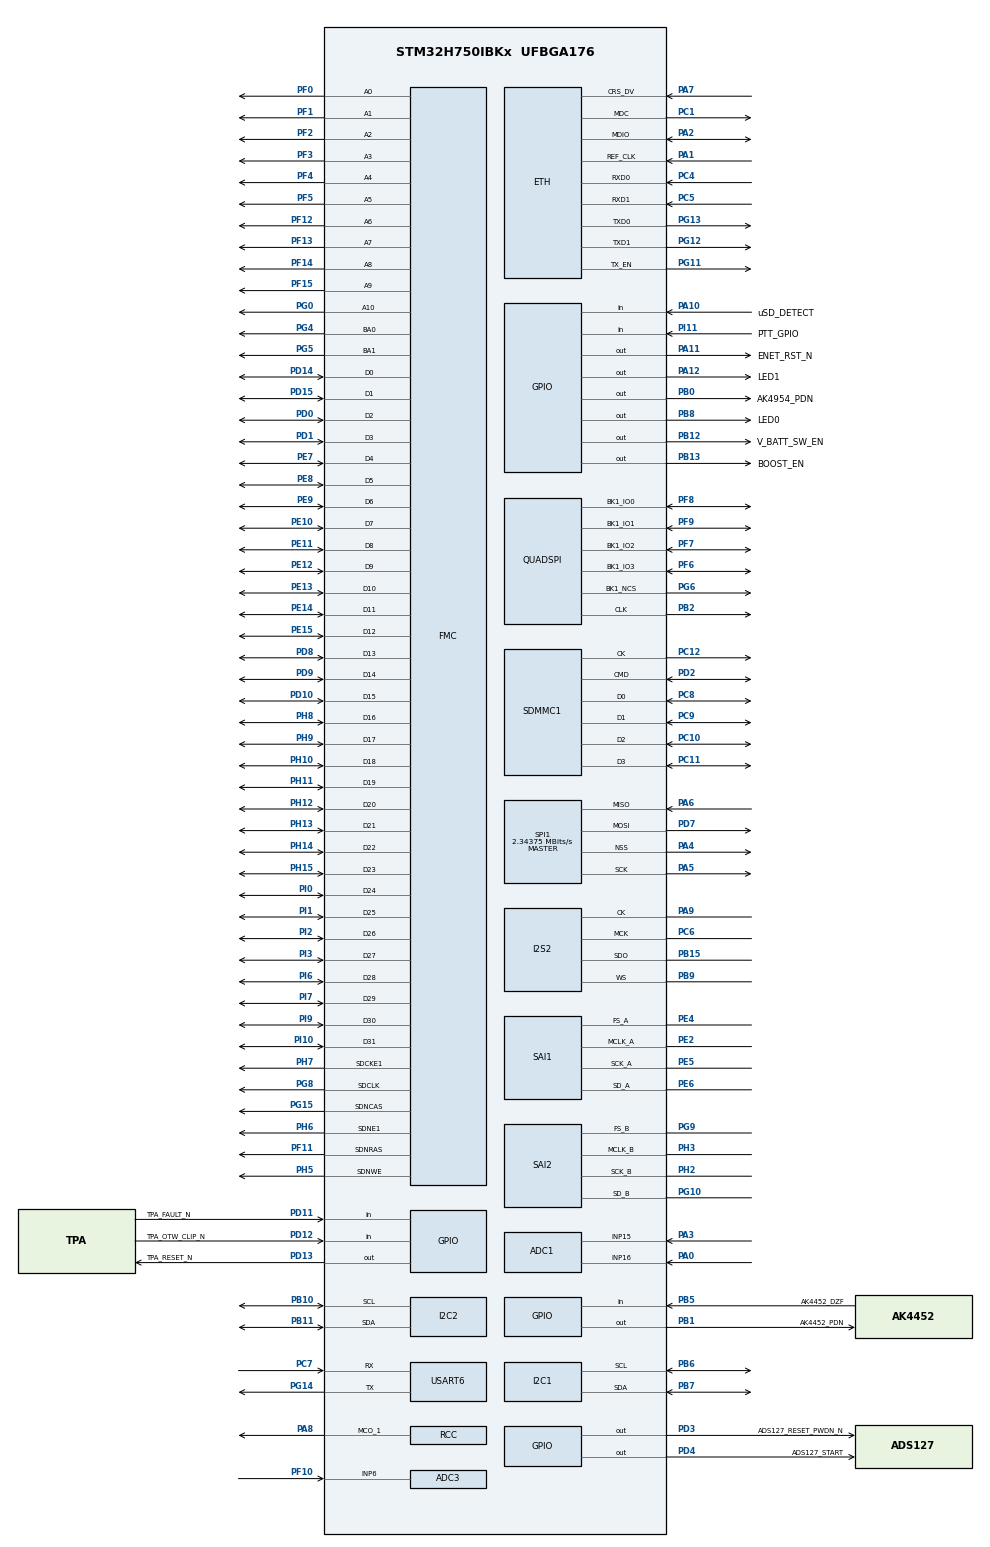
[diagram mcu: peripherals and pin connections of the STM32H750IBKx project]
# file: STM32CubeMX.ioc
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ADC1.Channel-0\#ChannelRegularConversion=ADC_CHANNEL_16
ADC1.ClockPrescaler=ADC_CLOCK_ASYNC_DIV16
ADC1.NbrOfConversionFlag=1
ADC1.OffsetNumber-0\#ChannelRegularConversion=ADC_OFFSET_NONE
ADC1.Rank-0\#ChannelRegularConversion=1
ADC1.SamplingTime-0\#ChannelRegularConversion=ADC_SAMPLETIME_1CYCLE_5
ADC1.master=1
ADC2.Channel-0\#ChannelRegularConversion=ADC_CHANNEL_15
ADC2.ClockPrescaler=ADC_CLOCK_ASYNC_DIV16
ADC2.NbrOfConversionFlag=1
ADC2.OffsetNumber-0\#ChannelRegularConversion=ADC_OFFSET_NONE
ADC2.Rank-0\#ChannelRegularConversion=1
ADC2.SamplingTime-0\#ChannelRegularConversion=ADC_SAMPLETIME_1CYCLE_5
ADC3.Channel-0\#ChannelRegularConversion=ADC_CHANNEL_6
ADC3.Channel-1\#ChannelRegularConversion=ADC_CHANNEL_6
ADC3.ClockPrescaler=ADC_CLOCK_ASYNC_DIV16
ADC3.NbrOfConversion=2
ADC3.NbrOfConversionFlag=1
ADC3.OffsetNumber-0\#ChannelRegularConversion=ADC_OFFSET_NONE
ADC3.OffsetNumber-1\#ChannelRegularConversion=ADC_OFFSET_NONE
ADC3.Rank-0\#ChannelRegularConversion=1
ADC3.Rank-1\#ChannelRegularConversion=2
ADC3.SamplingTime-0\#ChannelRegularConversion=ADC_SAMPLETIME_1CYCLE_5
ADC3.SamplingTime-1\#ChannelRegularConversion=ADC_SAMPLETIME_1CYCLE_5
Bdma.ADC3.0.Direction=DMA_PERIPH_TO_MEMORY
Bdma.ADC3.0.EventEnable=DISABLE
Bdma.ADC3.0.Instance=BDMA_Channel0
Bdma.ADC3.0.MemDataAlignment=DMA_MDATAALIGN_HALFWORD
Bdma.ADC3.0.MemInc=DMA_MINC_ENABLE
Bdma.ADC3.0.Mode=DMA_NORMAL
Bdma.ADC3.0.PeriphDataAlignment=DMA_PDATAALIGN_HALFWORD
Bdma.ADC3.0.PeriphInc=DMA_PINC_DISABLE
Bdma.ADC3.0.Polarity=HAL_DMAMUX_REQ_GEN_RISING
Bdma.ADC3.0.Priority=DMA_PRIORITY_LOW
Bdma.ADC3.0.RequestNumber=1
Bdma.ADC3.0.SignalID=NONE
Bdma.ADC3.0.SyncEnable=DISABLE
Bdma.ADC3.0.SyncPolarity=HAL_DMAMUX_SYNC_NO_EVENT
Bdma.ADC3.0.SyncRequestNumber=1
Bdma.ADC3.0.SyncSignalID=NONE
Bdma.Request0=ADC3
Bdma.RequestsNb=1
CORTEX_M7.CPU_DCache=Enabled
CORTEX_M7.CPU_ICache=Enabled
CORTEX_M7.MPU_Control=__NULL
Dma.Request0=SAI2_B
Dma.Request1=SAI1_A
Dma.Request2=SPI2_TX
Dma.SAI1_A.1.Direction=DMA_PERIPH_TO_MEMORY
Dma.SAI1_A.1.EventEnable=DISABLE
Dma.SAI1_A.1.FIFOMode=DMA_FIFOMODE_DISABLE
Dma.SAI1_A.1.Instance=DMA1_Stream2
Dma.SAI1_A.1.MemDataAlignment=DMA_MDATAALIGN_WORD
Dma.SAI1_A.1.MemInc=DMA_MINC_ENABLE
Dma.SAI1_A.1.Mode=DMA_CIRCULAR
Dma.SAI1_A.1.PeriphDataAlignment=DMA_PDATAALIGN_WORD
Dma.SAI1_A.1.PeriphInc=DMA_PINC_DISABLE
Dma.SAI1_A.1.Polarity=HAL_DMAMUX_REQ_GEN_RISING
Dma.SAI1_A.1.Priority=DMA_PRIORITY_LOW
Dma.SAI1_A.1.RequestNumber=1
Dma.SAI1_A.1.SignalID=NONE
Dma.SAI1_A.1.SyncEnable=DISABLE
Dma.SAI1_A.1.SyncPolarity=HAL_DMAMUX_SYNC_NO_EVENT
Dma.SAI1_A.1.SyncRequestNumber=1
Dma.SAI1_A.1.SyncSignalID=NONE
Dma.SAI2_B.0.Direction=DMA_MEMORY_TO_PERIPH
Dma.SAI2_B.0.EventEnable=ENABLE
Dma.SAI2_B.0.FIFOMode=DMA_FIFOMODE_DISABLE
Dma.SAI2_B.0.Instance=DMA1_Stream1
Dma.SAI2_B.0.MemDataAlignment=DMA_MDATAALIGN_WORD
Dma.SAI2_B.0.MemInc=DMA_MINC_ENABLE
Dma.SAI2_B.0.Mode=DMA_CIRCULAR
Dma.SAI2_B.0.PeriphDataAlignment=DMA_PDATAALIGN_WORD
Dma.SAI2_B.0.PeriphInc=DMA_PINC_DISABLE
Dma.SAI2_B.0.Polarity=HAL_DMAMUX_REQ_GEN_RISING
Dma.SAI2_B.0.Priority=DMA_PRIORITY_LOW
Dma.SAI2_B.0.RequestNumber=1
Dma.SAI2_B.0.SignalID=NONE
Dma.SAI2_B.0.SyncEnable=DISABLE
Dma.SAI2_B.0.SyncPolarity=HAL_DMAMUX_SYNC_NO_EVENT
Dma.SAI2_B.0.SyncRequestNumber=1
Dma.SAI2_B.0.SyncSignalID=NONE
Dma.SPI2_TX.2.Direction=DMA_MEMORY_TO_PERIPH
Dma.SPI2_TX.2.EventEnable=DISABLE
Dma.SPI2_TX.2.FIFOMode=DMA_FIFOMODE_ENABLE
Dma.SPI2_TX.2.FIFOThreshold=DMA_FIFO_THRESHOLD_HALFFULL
Dma.SPI2_TX.2.Instance=DMA1_Stream0
Dma.SPI2_TX.2.MemBurst=DMA_MBURST_SINGLE
Dma.SPI2_TX.2.MemDataAlignment=DMA_MDATAALIGN_WORD
Dma.SPI2_TX.2.MemInc=DMA_MINC_ENABLE
Dma.SPI2_TX.2.Mode=DMA_CIRCULAR
Dma.SPI2_TX.2.PeriphBurst=DMA_PBURST_SINGLE
Dma.SPI2_TX.2.PeriphDataAlignment=DMA_PDATAALIGN_WORD
Dma.SPI2_TX.2.PeriphInc=DMA_PINC_DISABLE
Dma.SPI2_TX.2.Polarity=HAL_DMAMUX_REQ_GEN_RISING
Dma.SPI2_TX.2.Priority=DMA_PRIORITY_VERY_HIGH
Dma.SPI2_TX.2.RequestNumber=1
Dma.SPI2_TX.2.SignalID=NONE
Dma.SPI2_TX.2.SyncEnable=DISABLE
Dma.SPI2_TX.2.SyncPolarity=HAL_DMAMUX_SYNC_NO_EVENT
Dma.SPI2_TX.2.SyncRequestNumber=1
Dma.SPI2_TX.2.SyncSignalID=NONE
ETH.MediaInterface=HAL_ETH_RMII_MODE
FMC.CASLatency1=FMC_SDRAM_CAS_LATENCY_2
FMC.ColumnBitsNumber1=FMC_SDRAM_COLUMN_BITS_NUM_8
FMC.ReadBurst1=FMC_SDRAM_RBURST_ENABLE
FMC.ReadPipeDelay1=FMC_SDRAM_RPIPE_DELAY_0
FMC.SDClockPeriod1=FMC_SDRAM_CLOCK_DISABLE
I2S2.AudioFreq=I2S_AUDIOFREQ_8K
I2S2.DataFormat=I2S_DATAFORMAT_32B
I2S2.ErrorAudioFreq=0.32 %
I2S2.FullDuplexMode=I2S_MODE_SLAVE_FD
I2S2.Instance=SPI$Index
I2S2.Mode=I2S_MODE_MASTER_TX
I2S2.RealAudioFreq=8.026 KHz
I2S2.VirtualMode=I2S_MODE_MASTER
Mcu.Family=STM32H7
Mcu.Name=STM32H750IBKx
Mcu.Package=UFBGA176
NVIC.BDMA_Channel0_IRQn=true\:0\:0\:false\:false\:true\:false\:true
NVIC.DMA1_Stream0_IRQn=true\:0\:0\:false\:false\:true\:false\:true
NVIC.DMA1_Stream1_IRQn=true\:0\:0\:false\:false\:true\:false\:true
NVIC.DMA1_Stream2_IRQn=true\:0\:0\:false\:false\:true\:false\:true
NVIC.DMAMUX1_OVR_IRQn=true\:0\:0\:false\:false\:true\:false\:true
NVIC.I2C1_ER_IRQn=true\:0\:0\:false\:false\:true\:true\:true
NVIC.I2C1_EV_IRQn=true\:0\:0\:false\:false\:true\:true\:true
NVIC.PriorityGroup=NVIC_PRIORITYGROUP_4
NVIC.SAI2_IRQn=true\:0\:0\:false\:false\:true\:true\:true
NVIC.SPI2_IRQn=true\:0\:0\:false\:false\:true\:true\:true
NVIC.TIM6_DAC_IRQn=true\:0\:0\:false\:false\:true\:false\:true
NVIC.TimeBase=TIM6_DAC_IRQn
NVIC.TimeBaseIP=TIM6
NVIC.USART6_IRQn=true\:0\:0\:false\:false\:true\:true\:true
PA0.Mode=IN16-Single-Ended
PA0.Signal=ADC1_INP16
PA1.Mode=RMII
PA1.Signal=ETH_REF_CLK
PA10.GPIO_Label=uSD_DETECT
PA10.Signal=GPIO_Input
PA11.GPIO_Label=ENET_RST_N
PA11.PinState=GPIO_PIN_SET
PA11.Signal=GPIO_Output
PA12.GPIO_Label=LED1
PA12.Signal=GPIO_Output
PA2.Mode=RMII
PA2.Signal=ETH_MDIO
PA3.Signal=ADCx_INP15
PA4.GPIO_Speed=GPIO_SPEED_FREQ_VERY_HIGH
PA4.Mode=NSS_Signal_Hard_Output
PA4.Signal=SPI1_NSS
PA5.Mode=Full_Duplex_Master
PA5.Signal=SPI1_SCK
PA6.Mode=Full_Duplex_Master
PA6.Signal=SPI1_MISO
PA7.Mode=RMII
PA7.Signal=ETH_CRS_DV
PA8.Mode=Clock-out-1
PA8.Signal=RCC_MCO_1
PA9.GPIO_Speed=GPIO_SPEED_FREQ_HIGH
PA9.Mode=Half_Duplex_Master
PA9.Signal=I2S2_CK
PB0.GPIO_Label=AK4954_PDN
PB0.Signal=GPIO_Output
PB1.GPIO_Label=AK4452_PDN
PB1.Signal=GPIO_Output
PB10.Mode=I2C
PB10.Signal=I2C2_SCL
PB11.Mode=I2C
PB11.Signal=I2C2_SDA
PB12.GPIO_Label=V_BATT_SW_EN
PB12.Signal=GPIO_Output
PB13.GPIO_Label=BOOST_EN
PB13.Signal=GPIO_Output
PB14.GPIO_Speed=GPIO_SPEED_FREQ_HIGH
PB14.Signal=I2S2_SDI
PB15.GPIO_Speed=GPIO_SPEED_FREQ_HIGH
PB15.Mode=Half_Duplex_Master
PB15.Signal=I2S2_SDO
PB2.Mode=Single Bank 1
PB2.Signal=QUADSPI_CLK
PB5.GPIO_Label=AK4452_DZF
PB5.Signal=GPIO_Input
PB6.Mode=I2C
PB6.Signal=I2C1_SCL
PB7.Mode=I2C
PB7.Signal=I2C1_SDA
PB8.GPIO_Label=LED0
PB8.Signal=GPIO_Output
PB9.GPIO_FM9=__NULL
PB9.GPIO_Speed=GPIO_SPEED_FREQ_HIGH
PB9.Mode=Half_Duplex_Master
PB9.Signal=I2S2_WS
PC0.Signal=ADCx_INP10
PC1.Mode=RMII
PC1.Signal=ETH_MDC
PC10.Mode=SD_4_bits_Wide_bus
PC10.Signal=SDMMC1_D2
PC11.Mode=SD_4_bits_Wide_bus
PC11.Signal=SDMMC1_D3
PC12.Mode=SD_4_bits_Wide_bus
PC12.Signal=SDMMC1_CK
PC14-OSC32_IN\ (OSC32_IN).Mode=LSE-External-Oscillator
PC14-OSC32_IN\ (OSC32_IN).Signal=RCC_OSC32_IN
PC15-OSC32_OUT\ (OSC32_OUT).Mode=LSE-External-Oscillator
PC15-OSC32_OUT\ (OSC32_OUT).Signal=RCC_OSC32_OUT
PC4.Mode=RMII
PC4.Signal=ETH_RXD0
PC5.Mode=RMII
PC5.Signal=ETH_RXD1
PC6.GPIO_Speed=GPIO_SPEED_FREQ_HIGH
PC6.Mode=Master_Clock_Activated
PC6.Signal=I2S2_MCK
PC7.Mode=Asynchronous
PC7.Signal=USART6_RX
PC8.Mode=SD_4_bits_Wide_bus
PC8.Signal=SDMMC1_D0
PC9.Mode=SD_4_bits_Wide_bus
PC9.Signal=SDMMC1_D1
PD0.Signal=FMC_D2_DA2
PD1.Signal=FMC_D3_DA3
PD10.Signal=FMC_D15_DA15
PD11.GPIO_Label=TPA_FAULT_N
PD11.Signal=GPIO_Input
PD12.GPIO_Label=TPA_OTW_CLIP_N
PD12.Signal=GPIO_Input
PD13.GPIO_Label=TPA_RESET_N
PD13.Signal=GPIO_Output
PD14.Signal=FMC_D0_DA0
PD15.Signal=FMC_D1_DA1
PD2.Mode=SD_4_bits_Wide_bus
PD2.Signal=SDMMC1_CMD
PD3.GPIO_Label=ADS127_RESET_PWDN_N
PD3.Signal=GPIO_Output
PD4.GPIO_Label=ADS127_START
PD4.Signal=GPIO_Output
PD5.Signal=USART2_TX
PD6.Signal=USART2_RX
PD7.Mode=Full_Duplex_Master
PD7.Signal=SPI1_MOSI
PD8.Signal=FMC_D13_DA13
PD9.Signal=FMC_D14_DA14
PE0.Signal=FMC_NBL0
PE1.Signal=FMC_NBL1
PE10.Signal=FMC_D7_DA7
PE11.Signal=FMC_D8_DA8
PE12.Signal=FMC_D9_DA9
PE13.Signal=FMC_D10_DA10
PE14.Signal=FMC_D11_DA11
PE15.Signal=FMC_D12_DA12
PE2.Mode=SAI_A_MasterWithClock
PE2.Signal=SAI1_MCLK_A
PE4.Mode=SAI_A_MasterWithClock
PE4.Signal=SAI1_FS_A
PE5.Mode=SAI_A_MasterWithClock
PE5.Signal=SAI1_SCK_A
PE6.Mode=SAI_A_MasterWithClock
PE6.Signal=SAI1_SD_A
PE7.Signal=FMC_D4_DA4
PE8.Signal=FMC_D5_DA5
PE9.Signal=FMC_D6_DA6
PF0.Signal=FMC_A0
PF1.Signal=FMC_A1
PF10.Mode=IN6-Single-Ended
PF10.Signal=ADC3_INP6
PF11.Signal=FMC_SDNRAS
PF12.Signal=FMC_A6
PF13.Signal=FMC_A7
PF14.Signal=FMC_A8
PF15.Signal=FMC_A9
PF2.Signal=FMC_A2
PF3.Signal=FMC_A3
PF4.Signal=FMC_A4
PF5.Signal=FMC_A5
PF6.Mode=Single Bank 1
PF6.Signal=QUADSPI_BK1_IO3
PF7.Mode=Single Bank 1
PF7.Signal=QUADSPI_BK1_IO2
PF8.Mode=Single Bank 1
PF8.Signal=QUADSPI_BK1_IO0
PF9.Mode=Single Bank 1
PF9.Signal=QUADSPI_BK1_IO1
PG0.Signal=FMC_A10
PG1.Signal=FMC_A11
PG10.Mode=SAI_B_MasterWithClock
PG10.Signal=SAI2_SD_B
PG11.Mode=RMII
PG11.Signal=ETH_TX_EN
PG12.Mode=RMII
PG12.Signal=ETH_TXD1
PG13.Mode=RMII
PG13.Signal=ETH_TXD0
PG14.Mode=Asynchronous
PG14.Signal=USART6_TX
PG15.Signal=FMC_SDNCAS
PG4.Signal=FMC_A14_BA0
PG5.Signal=FMC_A15_BA1
PG6.Mode=Single Bank 1
PG6.Signal=QUADSPI_BK1_NCS
PG8.Signal=FMC_SDCLK
PG9.Mode=SAI_B_MasterWithClock
PG9.Signal=SAI2_FS_B
PH0-OSC_IN\ (PH0).Mode=HSE-External-Oscillator
PH0-OSC_IN\ (PH0).Signal=RCC_OSC_IN
PH1-OSC_OUT\ (PH1).Mode=HSE-External-Oscillator
PH1-OSC_OUT\ (PH1).Signal=RCC_OSC_OUT
PH10.Signal=FMC_D18
PH11.Signal=FMC_D19
PH12.Signal=FMC_D20
PH13.Signal=FMC_D21
PH14.Signal=FMC_D22
PH15.Signal=FMC_D23
PH2.Mode=SAI_B_MasterWithClock
PH2.Signal=SAI2_SCK_B
PH3.GPIO_Mode=GPIO_MODE_AF_PP
PH3.GPIO_PuPd=GPIO_NOPULL
PH3.GPIO_Speed=GPIO_SPEED_FREQ_LOW
PH3.Mode=SAI_B_MasterWithClock
PH3.Signal=SAI2_MCLK_B
PH4.Signal=ADC3_INP15
PH5.Signal=FMC_SDNWE
PH6.Mode=SdramChipSelect2_1
PH6.Signal=FMC_SDNE1
PH7.Mode=SdramChipSelect2_1
PH7.Signal=FMC_SDCKE1
PH8.Signal=FMC_D16
PH9.Signal=FMC_D17
PI0.Signal=FMC_D24
PI1.Signal=FMC_D25
PI10.Signal=FMC_D31
PI11.GPIO_Label=PTT_GPIO
PI11.Signal=GPIO_Input
PI2.Signal=FMC_D26
PI3.Signal=FMC_D27
PI4.Signal=FMC_NBL2
PI5.Signal=FMC_NBL3
PI6.Signal=FMC_D28
PI7.Signal=FMC_D29
PI9.Signal=FMC_D30
ProjectManager.HeapSize=0x1000
ProjectManager.StackSize=0x1900
ProjectManager.TargetToolchain=STM32CubeIDE
RCC.ADCFreq_Value=150000000
RCC.APB1Freq_Value=40000000
RCC.APB2Freq_Value=40000000
RCC.APB3Freq_Value=40000000
RCC.APB4Freq_Value=40000000
RCC.CortexFreq_Value=80000000
RCC.D1PPRE=RCC_APB3_DIV2
RCC.D2PPRE1=RCC_APB1_DIV2
RCC.D2PPRE2=RCC_APB2_DIV2
RCC.D3PPRE=RCC_APB4_DIV2
RCC.DIVM1=2
RCC.DIVM2=2
RCC.DIVN1=64
RCC.DIVN2=12
RCC.DIVP1=10
RCC.DIVP2=1
RCC.DIVQ1=4
RCC.DIVQ2=4
RCC.DIVR2=1
RCC.HCLKFreq_Value=80000000
RCC.I2C123CLockSelection=RCC_I2C123CLKSOURCE_HSI
RCC.PLL2FRACN=0
RCC.PLL3FRACN=0
RCC.PLLFRACN=0
RCC.PLLSourceVirtual=RCC_PLLSOURCE_HSE
RCC.PWR_Regulator_Voltage_Scale=PWR_REGULATOR_VOLTAGE_SCALE1
RCC.QSPICLockSelection=RCC_QSPICLKSOURCE_PLL2
RCC.SAI1CLockSelection=RCC_SAI1CLKSOURCE_PLL2
RCC.SAI23CLockSelection=RCC_SAI23CLKSOURCE_PLL2
RCC.SDMMC1CLockSelection=RCC_SDMMCCLKSOURCE_PLL2
RCC.SPI123CLockSelection=RCC_SPI123CLKSOURCE_PLL2
RCC.SYSCLKFreq_VALUE=80000000
RCC.SYSCLKSource=RCC_SYSCLKSOURCE_PLLCLK
RCC.USBFreq_Value=200000000
SAI1.ActiveFrameLength-SAI_A_MasterWithClock=32
SAI1.AudioFrequency-SAI_A_MasterWithClock=SAI_AUDIO_FREQUENCY_MCKDIV
SAI1.AudioMode-SAI_A_MasterWithClock=SAI_MODEMASTER_RX
SAI1.DataSize-SAI_A_MasterWithClock=SAI_DATASIZE_32
SAI1.ErrorAudioFreq-SAI_A_MasterWithClock=-46.66 %
SAI1.FSOffset-SAI_A_MasterWithClock=SAI_FS_BEFOREFIRSTBIT
SAI1.FSPolarity-SAI_A_MasterWithClock=SAI_FS_ACTIVE_HIGH
SAI1.FirstBitOffset-SAI_A_MasterWithClock=0
SAI1.FrameLength-SAI_A_MasterWithClock=64
SAI1.Instance-SAI_A_MasterWithClock=SAI$Index_Block_A
SAI1.MClockEnable-SAI_A_MasterWithClock=SAI_MASTERCLOCK_ENABLE
SAI1.Mckdiv-SAI_A_MasterWithClock=1
SAI1.RealAudioFreq-SAI_A_MasterWithClock=292.968 KHz
SAI1.SlotActive-SAI_A_MasterWithClock=0x0000FFFF
SAI1.SlotNumber-SAI_A_MasterWithClock=2
SAI1.SlotSize-SAI_A_MasterWithClock=SAI_SLOTSIZE_32B
SAI1.Synchro-SAI_A_MasterWithClock=SAI_ASYNCHRONOUS
SAI1.VirtualMode-SAI_A_MasterWithClock=VM_MASTER
SAI1.VirtualSlotActive-SAI_A_MasterWithClock=SAI_SLOTACTIVE_ALL
SAI1.VirtualSlotActive0-SAI_A_MasterWithClock=false
SAI2.AudioFrequency-SAI_B_MasterWithClock=SAI_AUDIO_FREQUENCY_MCKDIV
SAI2.BasicDataSize-SAI_B_MasterWithClock=SAI_PROTOCOL_DATASIZE_32BIT
SAI2.BasicSlotNumber-SAI_B_MasterWithClock=2
SAI2.ErrorAudioFreq-SAI_B_MasterWithClock=-46.66 %
SAI2.InitProtocol-SAI_B_MasterWithClock=Enable
SAI2.Instance-SAI_B_MasterWithClock=SAI$Index_Block_B
SAI2.MClockEnable-SAI_B_MasterWithClock=SAI_MASTERCLOCK_ENABLE
SAI2.Mckdiv-SAI_B_MasterWithClock=2
SAI2.OutputDrive-SAI_B_MasterWithClock=SAI_OUTPUTDRIVE_ENABLE
SAI2.RealAudioFreq-SAI_B_MasterWithClock=146.484 KHz
SAI2.VirtualMode-SAI_B_MasterWithClock=VM_MASTER
SAI2.VirtualProtocol-SAI_B_BASIC=VM_BASIC_PROTOCOL
SDMMC1.ClockDiv=100
SDMMC1.HardwareFlowControl=SDMMC_HARDWARE_FLOW_CONTROL_ENABLE
SH.ADCx_INP10.0=ADC1_INP10
SH.ADCx_INP10.1=ADC3_INP10
SH.ADCx_INP15.0=ADC1_INP15,IN15-Single-Ended
SH.ADCx_INP15.1=ADC2_INP15,IN15-Single-Ended
SH.FMC_A0.0=FMC_A0,11b-sda1
SH.FMC_A1.0=FMC_A1,11b-sda1
SH.FMC_A10.0=FMC_A10,11b-sda1
SH.FMC_A11.0=FMC_A11
SH.FMC_A14_BA0.0=FMC_A14
SH.FMC_A14_BA0.1=FMC_BA0,FourSdramBanks1
SH.FMC_A15_BA1.0=FMC_A15
SH.FMC_A15_BA1.1=FMC_BA1,FourSdramBanks1
SH.FMC_A2.0=FMC_A2,11b-sda1
SH.FMC_A3.0=FMC_A3,11b-sda1
SH.FMC_A4.0=FMC_A4,11b-sda1
SH.FMC_A5.0=FMC_A5,11b-sda1
SH.FMC_A6.0=FMC_A6,11b-sda1
SH.FMC_A7.0=FMC_A7,11b-sda1
SH.FMC_A8.0=FMC_A8,11b-sda1
SH.FMC_A9.0=FMC_A9,11b-sda1
SH.FMC_D0_DA0.0=FMC_D0,sd-32b-d1
SH.FMC_D10_DA10.0=FMC_D10,sd-32b-d1
SH.FMC_D11_DA11.0=FMC_D11,sd-32b-d1
SH.FMC_D12_DA12.0=FMC_D12,sd-32b-d1
SH.FMC_D13_DA13.0=FMC_D13,sd-32b-d1
SH.FMC_D14_DA14.0=FMC_D14,sd-32b-d1
SH.FMC_D15_DA15.0=FMC_D15,sd-32b-d1
SH.FMC_D16.0=FMC_D16,sd-32b-d1
SH.FMC_D17.0=FMC_D17,sd-32b-d1
SH.FMC_D18.0=FMC_D18,sd-32b-d1
SH.FMC_D19.0=FMC_D19,sd-32b-d1
SH.FMC_D1_DA1.0=FMC_D1,sd-32b-d1
SH.FMC_D20.0=FMC_D20,sd-32b-d1
SH.FMC_D21.0=FMC_D21,sd-32b-d1
SH.FMC_D22.0=FMC_D22,sd-32b-d1
SH.FMC_D23.0=FMC_D23,sd-32b-d1
SH.FMC_D24.0=FMC_D24,sd-32b-d1
SH.FMC_D25.0=FMC_D25,sd-32b-d1
SH.FMC_D26.0=FMC_D26,sd-32b-d1
SH.FMC_D27.0=FMC_D27,sd-32b-d1
SH.FMC_D28.0=FMC_D28,sd-32b-d1
SH.FMC_D29.0=FMC_D29,sd-32b-d1
SH.FMC_D2_DA2.0=FMC_D2,sd-32b-d1
SH.FMC_D30.0=FMC_D30,sd-32b-d1
SH.FMC_D31.0=FMC_D31,sd-32b-d1
SH.FMC_D3_DA3.0=FMC_D3,sd-32b-d1
SH.FMC_D4_DA4.0=FMC_D4,sd-32b-d1
SH.FMC_D5_DA5.0=FMC_D5,sd-32b-d1
SH.FMC_D6_DA6.0=FMC_D6,sd-32b-d1
SH.FMC_D7_DA7.0=FMC_D7,sd-32b-d1
SH.FMC_D8_DA8.0=FMC_D8,sd-32b-d1
SH.FMC_D9_DA9.0=FMC_D9,sd-32b-d1
SH.FMC_NBL0.0=FMC_NBL0
SH.FMC_NBL1.0=FMC_NBL1
SH.FMC_NBL2.0=FMC_NBL2
SH.FMC_NBL3.0=FMC_NBL3
SH.FMC_SDCLK.0=FMC_SDCLK,11b-sda1
SH.FMC_SDNCAS.0=FMC_SDNCAS,11b-sda1
SH.FMC_SDNRAS.0=FMC_SDNRAS,11b-sda1
SH.FMC_SDNWE.0=FMC_SDNWE,11b-sda1
SPI1.BaudRatePrescaler=SPI_BAUDRATEPRESCALER_64
SPI1.CalculateBaudRate=2.34375 MBits/s
SPI1.DataSize=SPI_DATASIZE_32BIT
SPI1.Direction=SPI_DIRECTION_2LINES
SPI1.Mode=SPI_MODE_MASTER
SPI1.VirtualNSS=VM_NSSHARD
SPI1.VirtualType=VM_MASTER
USART6.VirtualMode-Asynchronous=VM_ASYNC
VP_RCC_LSE.Mode=CRS SYNC Source LSE
VP_SAI2_VP_$IpInstance_SAIB_SAI_BASIC.Mode=SAI_B_BASIC
VP_SYS_VS_tim6.Mode=TIM6
board=custom

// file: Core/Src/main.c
/* USER CODE BEGIN Header */
/**
  ******************************************************************************
  * @file           : main.c
  * @brief          : Main program body
  ******************************************************************************
  * @attention
  *
  * <h2><center>&copy; Copyright (c) 2020 STMicroelectronics.
  * All rights reserved.</center></h2>
  *
  * This software component is licensed by ST under Ultimate Liberty license
  * SLA0044, the "License"; You may not use this file except in compliance with
  * the License. You may obtain a copy of the License at:
  *                             www.st.com/SLA0044
  *
  ******************************************************************************
  */
/* USER CODE END Header */

#include "main.h"
#include "string.h"

#if defined ( __ICCARM__ ) /*!< IAR Compiler */

#pragma location=0x30040000
ETH_DMADescTypeDef  DMARxDscrTab[ETH_RX_DESC_CNT]; /* Ethernet Rx DMA Descriptors */
#pragma location=0x30040060
ETH_DMADescTypeDef  DMATxDscrTab[ETH_TX_DESC_CNT]; /* Ethernet Tx DMA Descriptors */
#pragma location=0x30040200
uint8_t Rx_Buff[ETH_RX_DESC_CNT][ETH_MAX_PACKET_SIZE]; /* Ethernet Receive Buffers */

#elif defined ( __CC_ARM )  /* MDK ARM Compiler */

__attribute__((at(0x30040000))) ETH_DMADescTypeDef  DMARxDscrTab[ETH_RX_DESC_CNT]; /* Ethernet Rx DMA Descriptors */
__attribute__((at(0x30040060))) ETH_DMADescTypeDef  DMATxDscrTab[ETH_TX_DESC_CNT]; /* Ethernet Tx DMA Descriptors */
__attribute__((at(0x30040200))) uint8_t Rx_Buff[ETH_RX_DESC_CNT][ETH_MAX_PACKET_SIZE]; /* Ethernet Receive Buffer */

#elif defined ( __GNUC__ ) /* GNU Compiler */

ETH_DMADescTypeDef DMARxDscrTab[ETH_RX_DESC_CNT] __attribute__((section(".RxDecripSection"))); /* Ethernet Rx DMA Descriptors */
ETH_DMADescTypeDef DMATxDscrTab[ETH_TX_DESC_CNT] __attribute__((section(".TxDecripSection")));   /* Ethernet Tx DMA Descriptors */
uint8_t Rx_Buff[ETH_RX_DESC_CNT][ETH_MAX_PACKET_SIZE] __attribute__((section(".RxArraySection"))); /* Ethernet Receive Buffers */

#endif

ETH_TxPacketConfig TxConfig;
ADC_HandleTypeDef hadc1;
ADC_HandleTypeDef hadc2;
ADC_HandleTypeDef hadc3;
DMA_HandleTypeDef hdma_adc3;

ETH_HandleTypeDef heth;

I2C_HandleTypeDef hi2c1;
I2C_HandleTypeDef hi2c2;

I2S_HandleTypeDef hi2s2;
DMA_HandleTypeDef hdma_spi2_tx;

QSPI_HandleTypeDef hqspi;

SAI_HandleTypeDef hsai_BlockA1;
SAI_HandleTypeDef hsai_BlockB2;
DMA_HandleTypeDef hdma_sai1_a;
DMA_HandleTypeDef hdma_sai2_b;

SD_HandleTypeDef hsd1;

SPI_HandleTypeDef hspi1;

UART_HandleTypeDef huart6;

SDRAM_HandleTypeDef hsdram1;

void SystemClock_Config(void);
static void MX_GPIO_Init(void);
static void MX_BDMA_Init(void);
static void MX_DMA_Init(void);
static void MX_SPI1_Init(void);
static void MX_ADC2_Init(void);
static void MX_SAI1_Init(void);
static void MX_ADC3_Init(void);
static void MX_QUADSPI_Init(void);
static void MX_SAI2_Init(void);
static void MX_I2S2_Init(void);
static void MX_USART6_UART_Init(void);
static void MX_I2C1_Init(void);
static void MX_I2C2_Init(void);
static void MX_SDMMC1_SD_Init(void);
static void MX_ADC1_Init(void);
static void MX_FMC_Init(void);
static void MX_ETH_Init(void);

int main(void)
{

  /* Enable I-Cache---------------------------------------------------------*/
  SCB_EnableICache();

  /* Enable D-Cache---------------------------------------------------------*/
  SCB_EnableDCache();

  /* MCU Configuration--------------------------------------------------------*/

  /* Reset of all peripherals, Initializes the Flash interface and the Systick. */
  HAL_Init();

  /* Configure the system clock */
  SystemClock_Config();

  /* Initialize all configured peripherals */
  MX_GPIO_Init();
  MX_BDMA_Init();
  MX_DMA_Init();
  MX_SPI1_Init();
  MX_ADC2_Init();
  MX_SAI1_Init();
  MX_ADC3_Init();
  MX_QUADSPI_Init();
  MX_SAI2_Init();
  MX_I2S2_Init();
  MX_USART6_UART_Init();
  MX_I2C1_Init();
  MX_I2C2_Init();
  MX_SDMMC1_SD_Init();
  MX_ADC1_Init();
  MX_FMC_Init();
  MX_ETH_Init();
  /* USER CODE BEGIN 2 */
  srand(100);
 int a[20];
  for( int i = 0 ; i <= 20 ; i++ ) {
        a[i] = rand() % 50;
     }

int volatile * const p_reg = (int *) 0xD0000000;
volatile int badcnt = 0;

{
	int i;

	int Last = -1;
	for (i = 0; i < 1000000; i++)
	{
		p_reg[i] = i;
	}
	for (i = 0; i < 1000000; i++)
		{
			if(p_reg[i] != i)
			{
				//printf("Bad At %h", i);

				badcnt ++;
			}
			Last=p_reg[i];
		}

}

  /*
  FIL filTest;
  FATFS fs;
  disk_initialize(0);
  FRESULT res = f_mount(&fs, "", 0);
  res = f_open(&filTest, "LOG.TXT", FA_OPEN_ALWAYS | FA_WRITE);
  if(res == FR_OK)
	  {
	    UINT BytesWritten;
	    const char string[] = "Hello World\n";

	    f_lseek(&filTest, f_size(&filTest));
	     res = f_write(&filTest, string, strlen(string), &BytesWritten);
	    f_close(&filTest);
	  }
*/
  /* USER CODE END 2 */

  /* Infinite loop */
  while (1)
  {

  }
}

void SystemClock_Config(void)
{
  RCC_OscInitTypeDef RCC_OscInitStruct = {0};
  RCC_ClkInitTypeDef RCC_ClkInitStruct = {0};
  RCC_PeriphCLKInitTypeDef PeriphClkInitStruct = {0};
  RCC_CRSInitTypeDef RCC_CRSInitStruct = {0};

  /** Supply configuration update enable
  */
  HAL_PWREx_ConfigSupply(PWR_LDO_SUPPLY);
  /** Configure the main internal regulator output voltage
  */
  __HAL_PWR_VOLTAGESCALING_CONFIG(PWR_REGULATOR_VOLTAGE_SCALE1);

  while(!__HAL_PWR_GET_FLAG(PWR_FLAG_VOSRDY)) {}
  /** Configure LSE Drive Capability
  */
  HAL_PWR_EnableBkUpAccess();
  __HAL_RCC_LSEDRIVE_CONFIG(RCC_LSEDRIVE_LOW);
  /** Macro to configure the PLL clock source
  */
  __HAL_RCC_PLL_PLLSOURCE_CONFIG(RCC_PLLSOURCE_HSE);
  /** Initializes the CPU, AHB and APB busses clocks
  */
  RCC_OscInitStruct.OscillatorType = RCC_OSCILLATORTYPE_HSI|RCC_OSCILLATORTYPE_HSE
                              |RCC_OSCILLATORTYPE_LSE;
  RCC_OscInitStruct.HSEState = RCC_HSE_ON;
  RCC_OscInitStruct.LSEState = RCC_LSE_ON;
  RCC_OscInitStruct.HSIState = RCC_HSI_DIV1;
  RCC_OscInitStruct.HSICalibrationValue = RCC_HSICALIBRATION_DEFAULT;
  RCC_OscInitStruct.PLL.PLLState = RCC_PLL_ON;
  RCC_OscInitStruct.PLL.PLLSource = RCC_PLLSOURCE_HSE;
  RCC_OscInitStruct.PLL.PLLM = 2;
  RCC_OscInitStruct.PLL.PLLN = 64;
  RCC_OscInitStruct.PLL.PLLP = 10;
  RCC_OscInitStruct.PLL.PLLQ = 4;
  RCC_OscInitStruct.PLL.PLLR = 2;
  RCC_OscInitStruct.PLL.PLLRGE = RCC_PLL1VCIRANGE_3;
  RCC_OscInitStruct.PLL.PLLVCOSEL = RCC_PLL1VCOWIDE;
  RCC_OscInitStruct.PLL.PLLFRACN = 0;
  if (HAL_RCC_OscConfig(&RCC_OscInitStruct) != HAL_OK)
  {
    Error_Handler();
  }
  /** Initializes the CPU, AHB and APB busses clocks
  */
  RCC_ClkInitStruct.ClockType = RCC_CLOCKTYPE_HCLK|RCC_CLOCKTYPE_SYSCLK
                              |RCC_CLOCKTYPE_PCLK1|RCC_CLOCKTYPE_PCLK2
                              |RCC_CLOCKTYPE_D3PCLK1|RCC_CLOCKTYPE_D1PCLK1;
  RCC_ClkInitStruct.SYSCLKSource = RCC_SYSCLKSOURCE_PLLCLK;
  RCC_ClkInitStruct.SYSCLKDivider = RCC_SYSCLK_DIV1;
  RCC_ClkInitStruct.AHBCLKDivider = RCC_HCLK_DIV1;
  RCC_ClkInitStruct.APB3CLKDivider = RCC_APB3_DIV2;
  RCC_ClkInitStruct.APB1CLKDivider = RCC_APB1_DIV2;
  RCC_ClkInitStruct.APB2CLKDivider = RCC_APB2_DIV2;
  RCC_ClkInitStruct.APB4CLKDivider = RCC_APB4_DIV2;

  if (HAL_RCC_ClockConfig(&RCC_ClkInitStruct, FLASH_LATENCY_1) != HAL_OK)
  {
    Error_Handler();
  }
  PeriphClkInitStruct.PeriphClockSelection = RCC_PERIPHCLK_USART6|RCC_PERIPHCLK_SPI1
                              |RCC_PERIPHCLK_SPI2|RCC_PERIPHCLK_SAI2
                              |RCC_PERIPHCLK_SAI1|RCC_PERIPHCLK_SDMMC
                              |RCC_PERIPHCLK_I2C2|RCC_PERIPHCLK_ADC
                              |RCC_PERIPHCLK_I2C1|RCC_PERIPHCLK_QSPI
                              |RCC_PERIPHCLK_FMC;
  PeriphClkInitStruct.PLL2.PLL2M = 2;
  PeriphClkInitStruct.PLL2.PLL2N = 12;
  PeriphClkInitStruct.PLL2.PLL2P = 1;
  PeriphClkInitStruct.PLL2.PLL2Q = 4;
  PeriphClkInitStruct.PLL2.PLL2R = 1;
  PeriphClkInitStruct.PLL2.PLL2RGE = RCC_PLL2VCIRANGE_3;
  PeriphClkInitStruct.PLL2.PLL2VCOSEL = RCC_PLL2VCOMEDIUM;
  PeriphClkInitStruct.PLL2.PLL2FRACN = 0;
  PeriphClkInitStruct.FmcClockSelection = RCC_FMCCLKSOURCE_D1HCLK;
  PeriphClkInitStruct.QspiClockSelection = RCC_QSPICLKSOURCE_PLL2;
  PeriphClkInitStruct.SdmmcClockSelection = RCC_SDMMCCLKSOURCE_PLL2;
  PeriphClkInitStruct.Sai1ClockSelection = RCC_SAI1CLKSOURCE_PLL2;
  PeriphClkInitStruct.Sai23ClockSelection = RCC_SAI23CLKSOURCE_PLL2;
  PeriphClkInitStruct.Spi123ClockSelection = RCC_SPI123CLKSOURCE_PLL2;
  PeriphClkInitStruct.Usart16ClockSelection = RCC_USART16CLKSOURCE_D2PCLK2;
  PeriphClkInitStruct.I2c123ClockSelection = RCC_I2C123CLKSOURCE_HSI;
  PeriphClkInitStruct.AdcClockSelection = RCC_ADCCLKSOURCE_PLL2;
  if (HAL_RCCEx_PeriphCLKConfig(&PeriphClkInitStruct) != HAL_OK)
  {
    Error_Handler();
  }
  HAL_RCC_MCOConfig(RCC_MCO1, RCC_MCO1SOURCE_HSI, RCC_MCODIV_1);
  /** Enable the SYSCFG APB clock
  */
  __HAL_RCC_CRS_CLK_ENABLE();
  /** Configures CRS
  */
  RCC_CRSInitStruct.Prescaler = RCC_CRS_SYNC_DIV1;
  RCC_CRSInitStruct.Source = RCC_CRS_SYNC_SOURCE_LSE;
  RCC_CRSInitStruct.Polarity = RCC_CRS_SYNC_POLARITY_RISING;
  RCC_CRSInitStruct.ReloadValue = __HAL_RCC_CRS_RELOADVALUE_CALCULATE(48000000,32768);
  RCC_CRSInitStruct.ErrorLimitValue = 34;
  RCC_CRSInitStruct.HSI48CalibrationValue = 32;

  HAL_RCCEx_CRSConfig(&RCC_CRSInitStruct);
}

static void MX_ADC1_Init(void)
{

  ADC_MultiModeTypeDef multimode = {0};
  ADC_ChannelConfTypeDef sConfig = {0};

  /** Common config
  */
  hadc1.Instance = ADC1;
  hadc1.Init.ClockPrescaler = ADC_CLOCK_ASYNC_DIV16;
  hadc1.Init.Resolution = ADC_RESOLUTION_16B;
  hadc1.Init.ScanConvMode = ADC_SCAN_DISABLE;
  hadc1.Init.EOCSelection = ADC_EOC_SINGLE_CONV;
  hadc1.Init.LowPowerAutoWait = DISABLE;
  hadc1.Init.ContinuousConvMode = DISABLE;
  hadc1.Init.NbrOfConversion = 1;
  hadc1.Init.DiscontinuousConvMode = DISABLE;
  hadc1.Init.ExternalTrigConv = ADC_SOFTWARE_START;
  hadc1.Init.ExternalTrigConvEdge = ADC_EXTERNALTRIGCONVEDGE_NONE;
  hadc1.Init.ConversionDataManagement = ADC_CONVERSIONDATA_DR;
  hadc1.Init.Overrun = ADC_OVR_DATA_PRESERVED;
  hadc1.Init.LeftBitShift = ADC_LEFTBITSHIFT_NONE;
  hadc1.Init.OversamplingMode = DISABLE;
  if (HAL_ADC_Init(&hadc1) != HAL_OK)
  {
    Error_Handler();
  }
  /** Configure the ADC multi-mode
  */
  multimode.Mode = ADC_MODE_INDEPENDENT;
  if (HAL_ADCEx_MultiModeConfigChannel(&hadc1, &multimode) != HAL_OK)
  {
    Error_Handler();
  }
  /** Configure Regular Channel
  */
  sConfig.Channel = ADC_CHANNEL_16;
  sConfig.Rank = ADC_REGULAR_RANK_1;
  sConfig.SamplingTime = ADC_SAMPLETIME_1CYCLE_5;
  sConfig.SingleDiff = ADC_SINGLE_ENDED;
  sConfig.OffsetNumber = ADC_OFFSET_NONE;
  sConfig.Offset = 0;
  if (HAL_ADC_ConfigChannel(&hadc1, &sConfig) != HAL_OK)
  {
    Error_Handler();
  }

}

static void MX_ADC2_Init(void)
{

  ADC_ChannelConfTypeDef sConfig = {0};

  /** Common config
  */
  hadc2.Instance = ADC2;
  hadc2.Init.ClockPrescaler = ADC_CLOCK_ASYNC_DIV16;
  hadc2.Init.Resolution = ADC_RESOLUTION_16B;
  hadc2.Init.ScanConvMode = ADC_SCAN_DISABLE;
  hadc2.Init.EOCSelection = ADC_EOC_SINGLE_CONV;
  hadc2.Init.LowPowerAutoWait = DISABLE;
  hadc2.Init.ContinuousConvMode = DISABLE;
  hadc2.Init.NbrOfConversion = 1;
  hadc2.Init.DiscontinuousConvMode = DISABLE;
  hadc2.Init.ExternalTrigConv = ADC_SOFTWARE_START;
  hadc2.Init.ExternalTrigConvEdge = ADC_EXTERNALTRIGCONVEDGE_NONE;
  hadc2.Init.ConversionDataManagement = ADC_CONVERSIONDATA_DR;
  hadc2.Init.Overrun = ADC_OVR_DATA_PRESERVED;
  hadc2.Init.LeftBitShift = ADC_LEFTBITSHIFT_NONE;
  hadc2.Init.OversamplingMode = DISABLE;
  if (HAL_ADC_Init(&hadc2) != HAL_OK)
  {
    Error_Handler();
  }
  /** Configure Regular Channel
  */
  sConfig.Channel = ADC_CHANNEL_15;
  sConfig.Rank = ADC_REGULAR_RANK_1;
  sConfig.SamplingTime = ADC_SAMPLETIME_1CYCLE_5;
  sConfig.SingleDiff = ADC_SINGLE_ENDED;
  sConfig.OffsetNumber = ADC_OFFSET_NONE;
  sConfig.Offset = 0;
  if (HAL_ADC_ConfigChannel(&hadc2, &sConfig) != HAL_OK)
  {
    Error_Handler();
  }

}

static void MX_ADC3_Init(void)
{

  ADC_ChannelConfTypeDef sConfig = {0};

  /** Common config
  */
  hadc3.Instance = ADC3;
  hadc3.Init.ClockPrescaler = ADC_CLOCK_ASYNC_DIV16;
  hadc3.Init.Resolution = ADC_RESOLUTION_16B;
  hadc3.Init.ScanConvMode = ADC_SCAN_ENABLE;
  hadc3.Init.EOCSelection = ADC_EOC_SINGLE_CONV;
  hadc3.Init.LowPowerAutoWait = DISABLE;
  hadc3.Init.ContinuousConvMode = DISABLE;
  hadc3.Init.NbrOfConversion = 2;
  hadc3.Init.DiscontinuousConvMode = DISABLE;
  hadc3.Init.ExternalTrigConv = ADC_SOFTWARE_START;
  hadc3.Init.ExternalTrigConvEdge = ADC_EXTERNALTRIGCONVEDGE_NONE;
  hadc3.Init.ConversionDataManagement = ADC_CONVERSIONDATA_DR;
  hadc3.Init.Overrun = ADC_OVR_DATA_PRESERVED;
  hadc3.Init.LeftBitShift = ADC_LEFTBITSHIFT_NONE;
  hadc3.Init.OversamplingMode = DISABLE;
  if (HAL_ADC_Init(&hadc3) != HAL_OK)
  {
    Error_Handler();
  }
  /** Configure Regular Channel
  */
  sConfig.Channel = ADC_CHANNEL_6;
  sConfig.Rank = ADC_REGULAR_RANK_1;
  sConfig.SamplingTime = ADC_SAMPLETIME_1CYCLE_5;
  sConfig.SingleDiff = ADC_SINGLE_ENDED;
  sConfig.OffsetNumber = ADC_OFFSET_NONE;
  sConfig.Offset = 0;
  if (HAL_ADC_ConfigChannel(&hadc3, &sConfig) != HAL_OK)
  {
    Error_Handler();
  }
  /** Configure Regular Channel
  */
  sConfig.Rank = ADC_REGULAR_RANK_2;
  if (HAL_ADC_ConfigChannel(&hadc3, &sConfig) != HAL_OK)
  {
    Error_Handler();
  }

}

static void MX_ETH_Init(void)
{

  heth.Instance = ETH;
  heth.Init.MACAddr[0] =   0x00;
  heth.Init.MACAddr[1] =   0x80;
  heth.Init.MACAddr[2] =   0xE1;
  heth.Init.MACAddr[3] =   0x00;
  heth.Init.MACAddr[4] =   0x00;
  heth.Init.MACAddr[5] =   0x00;
  heth.Init.MediaInterface = HAL_ETH_RMII_MODE;
  heth.Init.TxDesc = DMATxDscrTab;
  heth.Init.RxDesc = DMARxDscrTab;
  heth.Init.RxBuffLen = 1524;

  if (HAL_ETH_Init(&heth) != HAL_OK)
  {
    Error_Handler();
  }

  memset(&TxConfig, 0 , sizeof(ETH_TxPacketConfig));
  TxConfig.Attributes = ETH_TX_PACKETS_FEATURES_CSUM | ETH_TX_PACKETS_FEATURES_CRCPAD;
  TxConfig.ChecksumCtrl = ETH_CHECKSUM_IPHDR_PAYLOAD_INSERT_PHDR_CALC;
  TxConfig.CRCPadCtrl = ETH_CRC_PAD_INSERT;

}

static void MX_I2C1_Init(void)
{

  hi2c1.Instance = I2C1;
  hi2c1.Init.Timing = 0x10707DBC;
  hi2c1.Init.OwnAddress1 = 0;
  hi2c1.Init.AddressingMode = I2C_ADDRESSINGMODE_7BIT;
  hi2c1.Init.DualAddressMode = I2C_DUALADDRESS_DISABLE;
  hi2c1.Init.OwnAddress2 = 0;
  hi2c1.Init.OwnAddress2Masks = I2C_OA2_NOMASK;
  hi2c1.Init.GeneralCallMode = I2C_GENERALCALL_DISABLE;
  hi2c1.Init.NoStretchMode = I2C_NOSTRETCH_DISABLE;
  if (HAL_I2C_Init(&hi2c1) != HAL_OK)
  {
    Error_Handler();
  }
  /** Configure Analogue filter
  */
  if (HAL_I2CEx_ConfigAnalogFilter(&hi2c1, I2C_ANALOGFILTER_ENABLE) != HAL_OK)
  {
    Error_Handler();
  }
  /** Configure Digital filter
  */
  if (HAL_I2CEx_ConfigDigitalFilter(&hi2c1, 0) != HAL_OK)
  {
    Error_Handler();
  }

}

static void MX_I2C2_Init(void)
{

  hi2c2.Instance = I2C2;
  hi2c2.Init.Timing = 0x10707DBC;
  hi2c2.Init.OwnAddress1 = 0;
  hi2c2.Init.AddressingMode = I2C_ADDRESSINGMODE_7BIT;
  hi2c2.Init.DualAddressMode = I2C_DUALADDRESS_DISABLE;
  hi2c2.Init.OwnAddress2 = 0;
  hi2c2.Init.OwnAddress2Masks = I2C_OA2_NOMASK;
  hi2c2.Init.GeneralCallMode = I2C_GENERALCALL_DISABLE;
  hi2c2.Init.NoStretchMode = I2C_NOSTRETCH_DISABLE;
  if (HAL_I2C_Init(&hi2c2) != HAL_OK)
  {
    Error_Handler();
  }
  /** Configure Analogue filter
  */
  if (HAL_I2CEx_ConfigAnalogFilter(&hi2c2, I2C_ANALOGFILTER_ENABLE) != HAL_OK)
  {
    Error_Handler();
  }
  /** Configure Digital filter
  */
  if (HAL_I2CEx_ConfigDigitalFilter(&hi2c2, 0) != HAL_OK)
  {
    Error_Handler();
  }

}

static void MX_I2S2_Init(void)
{

  hi2s2.Instance = SPI2;
  hi2s2.Init.Mode = I2S_MODE_MASTER_TX;
  hi2s2.Init.Standard = I2S_STANDARD_PHILIPS;
  hi2s2.Init.DataFormat = I2S_DATAFORMAT_32B;
  hi2s2.Init.MCLKOutput = I2S_MCLKOUTPUT_ENABLE;
  hi2s2.Init.AudioFreq = I2S_AUDIOFREQ_8K;
  hi2s2.Init.CPOL = I2S_CPOL_LOW;
  hi2s2.Init.FirstBit = I2S_FIRSTBIT_MSB;
  hi2s2.Init.WSInversion = I2S_WS_INVERSION_DISABLE;
  hi2s2.Init.Data24BitAlignment = I2S_DATA_24BIT_ALIGNMENT_RIGHT;
  hi2s2.Init.MasterKeepIOState = I2S_MASTER_KEEP_IO_STATE_DISABLE;
  if (HAL_I2S_Init(&hi2s2) != HAL_OK)
  {
    Error_Handler();
  }

}

static void MX_QUADSPI_Init(void)
{

  /* QUADSPI parameter configuration*/
  hqspi.Instance = QUADSPI;
  hqspi.Init.ClockPrescaler = 255;
  hqspi.Init.FifoThreshold = 1;
  hqspi.Init.SampleShifting = QSPI_SAMPLE_SHIFTING_NONE;
  hqspi.Init.FlashSize = 1;
  hqspi.Init.ChipSelectHighTime = QSPI_CS_HIGH_TIME_1_CYCLE;
  hqspi.Init.ClockMode = QSPI_CLOCK_MODE_0;
  hqspi.Init.FlashID = QSPI_FLASH_ID_1;
  hqspi.Init.DualFlash = QSPI_DUALFLASH_DISABLE;
  if (HAL_QSPI_Init(&hqspi) != HAL_OK)
  {
    Error_Handler();
  }

}

static void MX_SAI1_Init(void)
{

  hsai_BlockA1.Instance = SAI1_Block_A;
  hsai_BlockA1.Init.Protocol = SAI_FREE_PROTOCOL;
  hsai_BlockA1.Init.AudioMode = SAI_MODEMASTER_RX;
  hsai_BlockA1.Init.DataSize = SAI_DATASIZE_32;
  hsai_BlockA1.Init.FirstBit = SAI_FIRSTBIT_MSB;
  hsai_BlockA1.Init.ClockStrobing = SAI_CLOCKSTROBING_FALLINGEDGE;
  hsai_BlockA1.Init.Synchro = SAI_ASYNCHRONOUS;
  hsai_BlockA1.Init.OutputDrive = SAI_OUTPUTDRIVE_DISABLE;
  hsai_BlockA1.Init.NoDivider = SAI_MASTERDIVIDER_ENABLE;
  hsai_BlockA1.Init.FIFOThreshold = SAI_FIFOTHRESHOLD_EMPTY;
  hsai_BlockA1.Init.AudioFrequency = SAI_AUDIO_FREQUENCY_MCKDIV;
  hsai_BlockA1.Init.Mckdiv = 1;
  hsai_BlockA1.Init.SynchroExt = SAI_SYNCEXT_DISABLE;
  hsai_BlockA1.Init.MonoStereoMode = SAI_STEREOMODE;
  hsai_BlockA1.Init.CompandingMode = SAI_NOCOMPANDING;
  hsai_BlockA1.Init.PdmInit.Activation = DISABLE;
  hsai_BlockA1.Init.PdmInit.MicPairsNbr = 1;
  hsai_BlockA1.Init.PdmInit.ClockEnable = SAI_PDM_CLOCK1_ENABLE;
  hsai_BlockA1.FrameInit.FrameLength = 64;
  hsai_BlockA1.FrameInit.ActiveFrameLength = 32;
  hsai_BlockA1.FrameInit.FSDefinition = SAI_FS_STARTFRAME;
  hsai_BlockA1.FrameInit.FSPolarity = SAI_FS_ACTIVE_HIGH;
  hsai_BlockA1.FrameInit.FSOffset = SAI_FS_BEFOREFIRSTBIT;
  hsai_BlockA1.SlotInit.FirstBitOffset = 0;
  hsai_BlockA1.SlotInit.SlotSize = SAI_SLOTSIZE_32B;
  hsai_BlockA1.SlotInit.SlotNumber = 2;
  hsai_BlockA1.SlotInit.SlotActive = 0x0000FFFF;
  if (HAL_SAI_Init(&hsai_BlockA1) != HAL_OK)
  {
    Error_Handler();
  }

}

static void MX_SAI2_Init(void)
{

  hsai_BlockB2.Instance = SAI2_Block_B;
  hsai_BlockB2.Init.AudioMode = SAI_MODEMASTER_TX;
  hsai_BlockB2.Init.Synchro = SAI_ASYNCHRONOUS;
  hsai_BlockB2.Init.OutputDrive = SAI_OUTPUTDRIVE_ENABLE;
  hsai_BlockB2.Init.NoDivider = SAI_MASTERDIVIDER_ENABLE;
  hsai_BlockB2.Init.FIFOThreshold = SAI_FIFOTHRESHOLD_EMPTY;
  hsai_BlockB2.Init.AudioFrequency = SAI_AUDIO_FREQUENCY_MCKDIV;
  hsai_BlockB2.Init.Mckdiv = 2;
  hsai_BlockB2.Init.SynchroExt = SAI_SYNCEXT_DISABLE;
  hsai_BlockB2.Init.MonoStereoMode = SAI_STEREOMODE;
  hsai_BlockB2.Init.CompandingMode = SAI_NOCOMPANDING;
  hsai_BlockB2.Init.TriState = SAI_OUTPUT_NOTRELEASED;
  if (HAL_SAI_InitProtocol(&hsai_BlockB2, SAI_I2S_STANDARD, SAI_PROTOCOL_DATASIZE_32BIT, 2) != HAL_OK)
  {
    Error_Handler();
  }

}

static void MX_SDMMC1_SD_Init(void)
{

  hsd1.Instance = SDMMC1;
  hsd1.Init.ClockEdge = SDMMC_CLOCK_EDGE_RISING;
  hsd1.Init.ClockPowerSave = SDMMC_CLOCK_POWER_SAVE_DISABLE;
  hsd1.Init.BusWide = SDMMC_BUS_WIDE_4B;
  hsd1.Init.HardwareFlowControl = SDMMC_HARDWARE_FLOW_CONTROL_ENABLE;
  hsd1.Init.ClockDiv = 100;
  hsd1.Init.TranceiverPresent = SDMMC_TRANSCEIVER_NOT_PRESENT;
  if (HAL_SD_Init(&hsd1) != HAL_OK)
  {
    Error_Handler();
  }

}

static void MX_SPI1_Init(void)
{

  /* SPI1 parameter configuration*/
  hspi1.Instance = SPI1;
  hspi1.Init.Mode = SPI_MODE_MASTER;
  hspi1.Init.Direction = SPI_DIRECTION_2LINES;
  hspi1.Init.DataSize = SPI_DATASIZE_32BIT;
  hspi1.Init.CLKPolarity = SPI_POLARITY_LOW;
  hspi1.Init.CLKPhase = SPI_PHASE_1EDGE;
  hspi1.Init.NSS = SPI_NSS_HARD_OUTPUT;
  hspi1.Init.BaudRatePrescaler = SPI_BAUDRATEPRESCALER_64;
  hspi1.Init.FirstBit = SPI_FIRSTBIT_MSB;
  hspi1.Init.TIMode = SPI_TIMODE_DISABLE;
  hspi1.Init.CRCCalculation = SPI_CRCCALCULATION_DISABLE;
  hspi1.Init.CRCPolynomial = 0x0;
  hspi1.Init.NSSPMode = SPI_NSS_PULSE_ENABLE;
  hspi1.Init.NSSPolarity = SPI_NSS_POLARITY_LOW;
  hspi1.Init.FifoThreshold = SPI_FIFO_THRESHOLD_01DATA;
  hspi1.Init.TxCRCInitializationPattern = SPI_CRC_INITIALIZATION_ALL_ZERO_PATTERN;
  hspi1.Init.RxCRCInitializationPattern = SPI_CRC_INITIALIZATION_ALL_ZERO_PATTERN;
  hspi1.Init.MasterSSIdleness = SPI_MASTER_SS_IDLENESS_00CYCLE;
  hspi1.Init.MasterInterDataIdleness = SPI_MASTER_INTERDATA_IDLENESS_00CYCLE;
  hspi1.Init.MasterReceiverAutoSusp = SPI_MASTER_RX_AUTOSUSP_DISABLE;
  hspi1.Init.MasterKeepIOState = SPI_MASTER_KEEP_IO_STATE_DISABLE;
  hspi1.Init.IOSwap = SPI_IO_SWAP_DISABLE;
  if (HAL_SPI_Init(&hspi1) != HAL_OK)
  {
    Error_Handler();
  }

}

static void MX_USART6_UART_Init(void)
{

  huart6.Instance = USART6;
  huart6.Init.BaudRate = 115200;
  huart6.Init.WordLength = UART_WORDLENGTH_8B;
  huart6.Init.StopBits = UART_STOPBITS_1;
  huart6.Init.Parity = UART_PARITY_NONE;
  huart6.Init.Mode = UART_MODE_TX_RX;
  huart6.Init.HwFlowCtl = UART_HWCONTROL_NONE;
  huart6.Init.OverSampling = UART_OVERSAMPLING_16;
  huart6.Init.OneBitSampling = UART_ONE_BIT_SAMPLE_DISABLE;
  huart6.Init.ClockPrescaler = UART_PRESCALER_DIV1;
  huart6.AdvancedInit.AdvFeatureInit = UART_ADVFEATURE_NO_INIT;
  if (HAL_UART_Init(&huart6) != HAL_OK)
  {
    Error_Handler();
  }
  if (HAL_UARTEx_SetTxFifoThreshold(&huart6, UART_TXFIFO_THRESHOLD_1_8) != HAL_OK)
  {
    Error_Handler();
  }
  if (HAL_UARTEx_SetRxFifoThreshold(&huart6, UART_RXFIFO_THRESHOLD_1_8) != HAL_OK)
  {
    Error_Handler();
  }
  if (HAL_UARTEx_DisableFifoMode(&huart6) != HAL_OK)
  {
    Error_Handler();
  }

}

static void MX_BDMA_Init(void)
{

  /* DMA controller clock enable */
  __HAL_RCC_BDMA_CLK_ENABLE();

  /* DMA interrupt init */
  /* BDMA_Channel0_IRQn interrupt configuration */
  HAL_NVIC_SetPriority(BDMA_Channel0_IRQn, 0, 0);
  HAL_NVIC_EnableIRQ(BDMA_Channel0_IRQn);

}

static void MX_DMA_Init(void)
{

  /* DMA controller clock enable */
  __HAL_RCC_DMA1_CLK_ENABLE();

  /* DMA interrupt init */
  /* DMA1_Stream0_IRQn interrupt configuration */
  HAL_NVIC_SetPriority(DMA1_Stream0_IRQn, 0, 0);
  HAL_NVIC_EnableIRQ(DMA1_Stream0_IRQn);
  /* DMA1_Stream1_IRQn interrupt configuration */
  HAL_NVIC_SetPriority(DMA1_Stream1_IRQn, 0, 0);
  HAL_NVIC_EnableIRQ(DMA1_Stream1_IRQn);
  /* DMA1_Stream2_IRQn interrupt configuration */
  HAL_NVIC_SetPriority(DMA1_Stream2_IRQn, 0, 0);
  HAL_NVIC_EnableIRQ(DMA1_Stream2_IRQn);
  /* DMAMUX1_OVR_IRQn interrupt configuration */
  HAL_NVIC_SetPriority(DMAMUX1_OVR_IRQn, 0, 0);
  HAL_NVIC_EnableIRQ(DMAMUX1_OVR_IRQn);

}

/* FMC initialization function */
static void MX_FMC_Init(void)
{

  FMC_SDRAM_TimingTypeDef SdramTiming = {0};

  /** Perform the SDRAM1 memory initialization sequence
  */
  hsdram1.Instance = FMC_SDRAM_DEVICE;
  /* hsdram1.Init */
  hsdram1.Init.SDBank = FMC_SDRAM_BANK2;
  hsdram1.Init.ColumnBitsNumber = FMC_SDRAM_COLUMN_BITS_NUM_8;
  hsdram1.Init.RowBitsNumber = FMC_SDRAM_ROW_BITS_NUM_11;
  hsdram1.Init.MemoryDataWidth = FMC_SDRAM_MEM_BUS_WIDTH_32;
  hsdram1.Init.InternalBankNumber = FMC_SDRAM_INTERN_BANKS_NUM_4;
  hsdram1.Init.CASLatency = FMC_SDRAM_CAS_LATENCY_2;
  hsdram1.Init.WriteProtection = FMC_SDRAM_WRITE_PROTECTION_DISABLE;
  hsdram1.Init.SDClockPeriod = FMC_SDRAM_CLOCK_DISABLE;
  hsdram1.Init.ReadBurst = FMC_SDRAM_RBURST_ENABLE;
  hsdram1.Init.ReadPipeDelay = FMC_SDRAM_RPIPE_DELAY_0;
  /* SdramTiming */
  SdramTiming.LoadToActiveDelay = 16;
  SdramTiming.ExitSelfRefreshDelay = 16;
  SdramTiming.SelfRefreshTime = 16;
  SdramTiming.RowCycleDelay = 16;
  SdramTiming.WriteRecoveryTime = 16;
  SdramTiming.RPDelay = 16;
  SdramTiming.RCDDelay = 16;

  if (HAL_SDRAM_Init(&hsdram1, &SdramTiming) != HAL_OK)
  {
    Error_Handler( );
  }

}

static void MX_GPIO_Init(void)
{
  GPIO_InitTypeDef GPIO_InitStruct = {0};

  /* GPIO Ports Clock Enable */
  __HAL_RCC_GPIOE_CLK_ENABLE();
  __HAL_RCC_GPIOB_CLK_ENABLE();
  __HAL_RCC_GPIOG_CLK_ENABLE();
  __HAL_RCC_GPIOD_CLK_ENABLE();
  __HAL_RCC_GPIOC_CLK_ENABLE();
  __HAL_RCC_GPIOA_CLK_ENABLE();
  __HAL_RCC_GPIOI_CLK_ENABLE();
  __HAL_RCC_GPIOH_CLK_ENABLE();
  __HAL_RCC_GPIOF_CLK_ENABLE();

  /*Configure GPIO pin Output Level */
  HAL_GPIO_WritePin(GPIOB, LED0_Pin|V_BATT_SW_EN_Pin|BOOST_EN_Pin|AK4452_PDN_Pin
                          |AK4954_PDN_Pin, GPIO_PIN_RESET);

  /*Configure GPIO pin Output Level */
  HAL_GPIO_WritePin(LED1_GPIO_Port, LED1_Pin, GPIO_PIN_RESET);

  /*Configure GPIO pin Output Level */
  HAL_GPIO_WritePin(ENET_RST_N_GPIO_Port, ENET_RST_N_Pin, GPIO_PIN_SET);

  /*Configure GPIO pin Output Level */
  HAL_GPIO_WritePin(GPIOD, ADS127_START_Pin|ADS127_RESET_PWDN_N_Pin|TPA_RESET_N_Pin, GPIO_PIN_RESET);

  /*Configure GPIO pins : LED0_Pin V_BATT_SW_EN_Pin BOOST_EN_Pin AK4452_PDN_Pin
                           AK4954_PDN_Pin */
  GPIO_InitStruct.Pin = LED0_Pin|V_BATT_SW_EN_Pin|BOOST_EN_Pin|AK4452_PDN_Pin
                          |AK4954_PDN_Pin;
  GPIO_InitStruct.Mode = GPIO_MODE_OUTPUT_PP;
  GPIO_InitStruct.Pull = GPIO_NOPULL;
  GPIO_InitStruct.Speed = GPIO_SPEED_FREQ_LOW;
  HAL_GPIO_Init(GPIOB, &GPIO_InitStruct);

  /*Configure GPIO pin : AK4452_DZF_Pin */
  GPIO_InitStruct.Pin = AK4452_DZF_Pin;
  GPIO_InitStruct.Mode = GPIO_MODE_INPUT;
  GPIO_InitStruct.Pull = GPIO_NOPULL;
  HAL_GPIO_Init(AK4452_DZF_GPIO_Port, &GPIO_InitStruct);

  /*Configure GPIO pins : PD6 PD5 */
  GPIO_InitStruct.Pin = GPIO_PIN_6|GPIO_PIN_5;
  GPIO_InitStruct.Mode = GPIO_MODE_AF_PP;
  GPIO_InitStruct.Pull = GPIO_NOPULL;
  GPIO_InitStruct.Speed = GPIO_SPEED_FREQ_LOW;
  GPIO_InitStruct.Alternate = GPIO_AF7_USART2;
  HAL_GPIO_Init(GPIOD, &GPIO_InitStruct);

  /*Configure GPIO pins : LED1_Pin ENET_RST_N_Pin */
  GPIO_InitStruct.Pin = LED1_Pin|ENET_RST_N_Pin;
  GPIO_InitStruct.Mode = GPIO_MODE_OUTPUT_PP;
  GPIO_InitStruct.Pull = GPIO_NOPULL;
  GPIO_InitStruct.Speed = GPIO_SPEED_FREQ_LOW;
  HAL_GPIO_Init(GPIOA, &GPIO_InitStruct);

  /*Configure GPIO pins : ADS127_START_Pin ADS127_RESET_PWDN_N_Pin TPA_RESET_N_Pin */
  GPIO_InitStruct.Pin = ADS127_START_Pin|ADS127_RESET_PWDN_N_Pin|TPA_RESET_N_Pin;
  GPIO_InitStruct.Mode = GPIO_MODE_OUTPUT_PP;
  GPIO_InitStruct.Pull = GPIO_NOPULL;
  GPIO_InitStruct.Speed = GPIO_SPEED_FREQ_LOW;
  HAL_GPIO_Init(GPIOD, &GPIO_InitStruct);

  /*Configure GPIO pin : uSD_DETECT_Pin */
  GPIO_InitStruct.Pin = uSD_DETECT_Pin;
  GPIO_InitStruct.Mode = GPIO_MODE_INPUT;
  GPIO_InitStruct.Pull = GPIO_NOPULL;
  HAL_GPIO_Init(uSD_DETECT_GPIO_Port, &GPIO_InitStruct);

  /*Configure GPIO pin : PTT_GPIO_Pin */
  GPIO_InitStruct.Pin = PTT_GPIO_Pin;
  GPIO_InitStruct.Mode = GPIO_MODE_INPUT;
  GPIO_InitStruct.Pull = GPIO_NOPULL;
  HAL_GPIO_Init(PTT_GPIO_GPIO_Port, &GPIO_InitStruct);

  /*Configure GPIO pin : PA8 */
  GPIO_InitStruct.Pin = GPIO_PIN_8;
  GPIO_InitStruct.Mode = GPIO_MODE_AF_PP;
  GPIO_InitStruct.Pull = GPIO_NOPULL;
  GPIO_InitStruct.Speed = GPIO_SPEED_FREQ_LOW;
  GPIO_InitStruct.Alternate = GPIO_AF0_MCO;
  HAL_GPIO_Init(GPIOA, &GPIO_InitStruct);

  /*Configure GPIO pins : TPA_OTW_CLIP_N_Pin TPA_FAULT_N_Pin */
  GPIO_InitStruct.Pin = TPA_OTW_CLIP_N_Pin|TPA_FAULT_N_Pin;
  GPIO_InitStruct.Mode = GPIO_MODE_INPUT;
  GPIO_InitStruct.Pull = GPIO_NOPULL;
  HAL_GPIO_Init(GPIOD, &GPIO_InitStruct);

}

void HAL_TIM_PeriodElapsedCallback(TIM_HandleTypeDef *htim)
{
  if (htim->Instance == TIM6) {
    HAL_IncTick();
  }
}

void Error_Handler(void)
{
}

/************************ (C) COPYRIGHT STMicroelectronics *****END OF FILE****/
